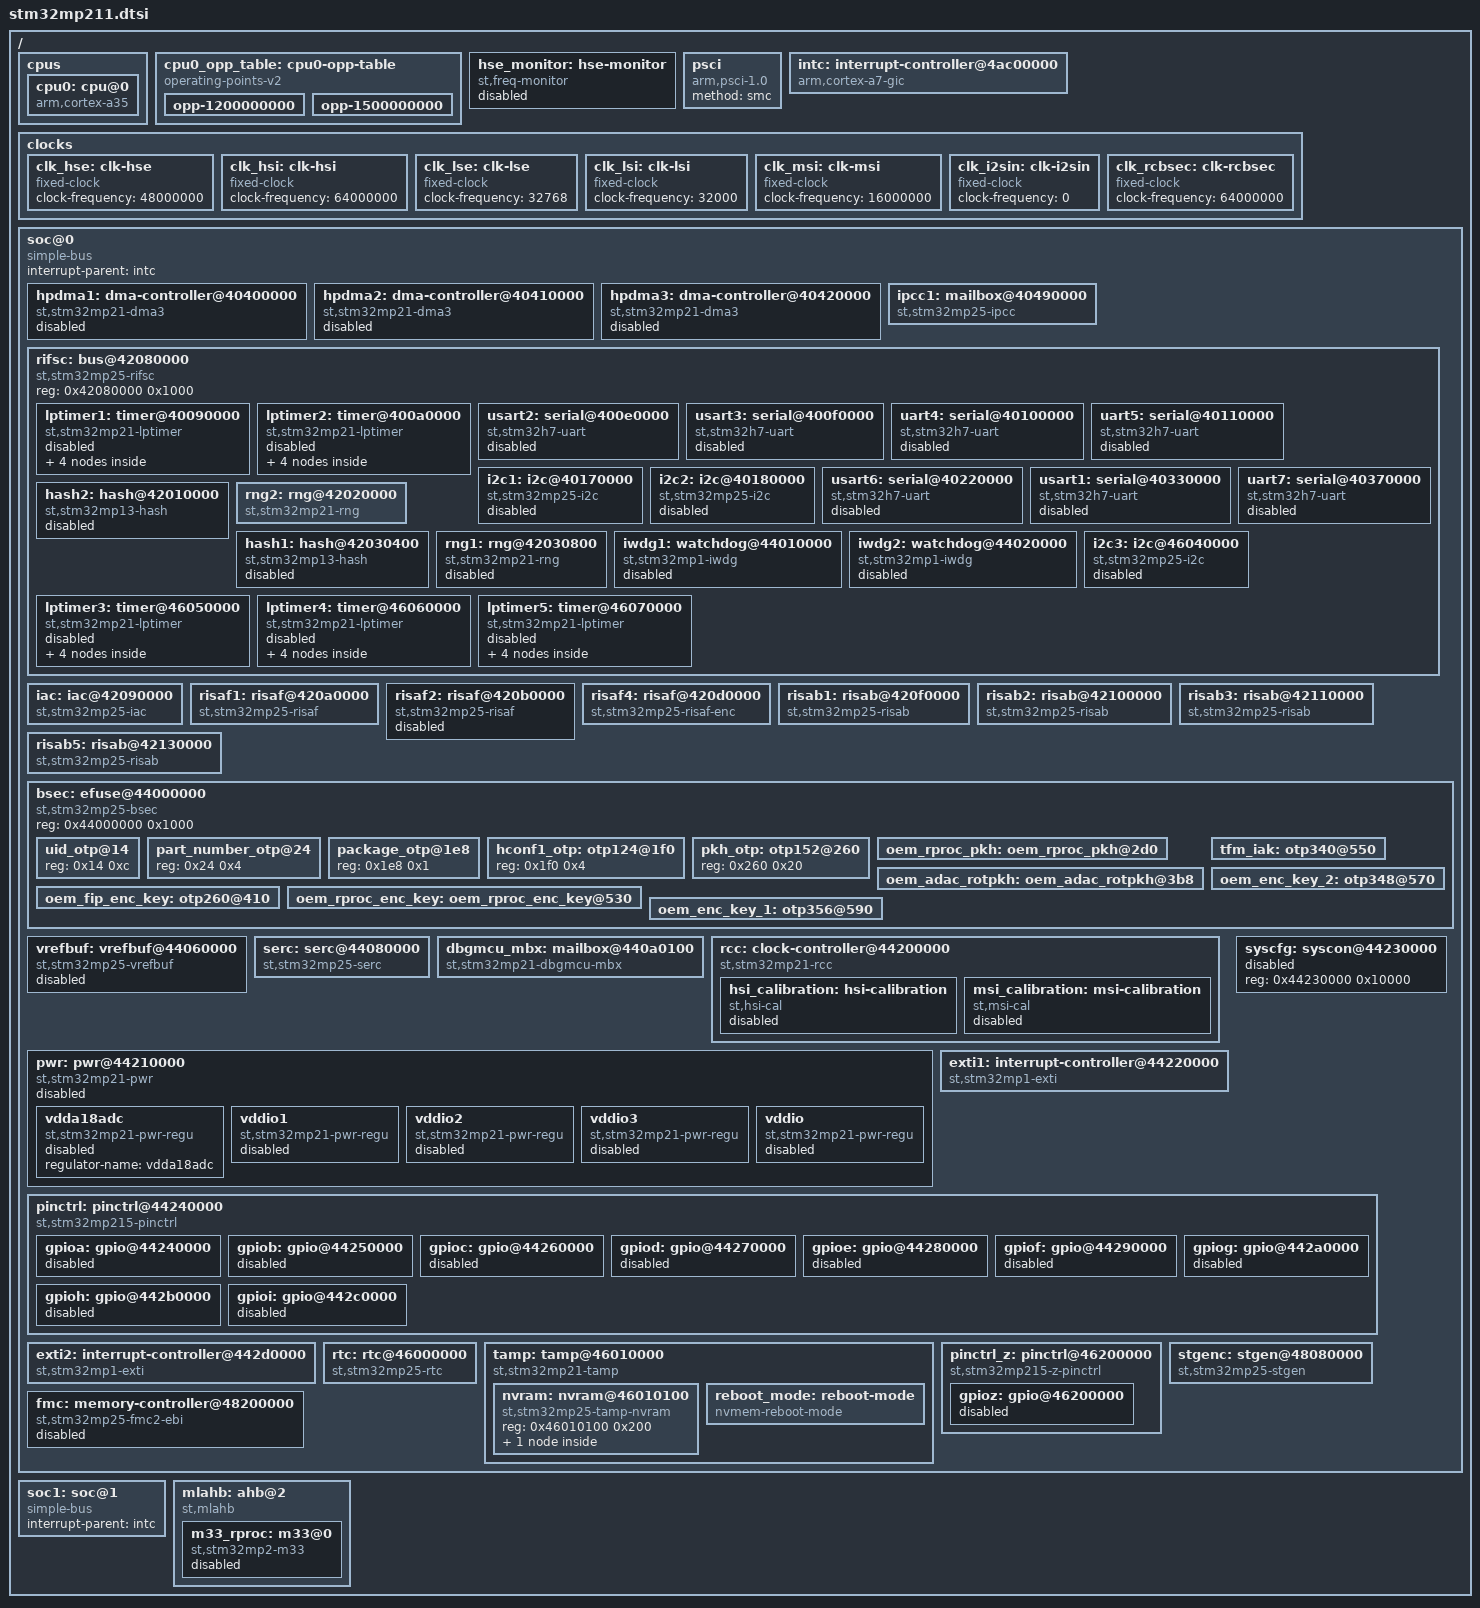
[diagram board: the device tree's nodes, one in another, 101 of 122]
// SPDX-License-Identifier: (GPL-2.0-only OR BSD-3-Clause)
/*
 * Copyright (C) 2025, STMicroelectronics - All Rights Reserved
 * Author: Alexandre Torgue <alexandre.torgue@foss.st.com> for STMicroelectronics.
 */
#include <dt-bindings/clock/st,stm32mp21-rcc.h>
#include <dt-bindings/gpio/gpio.h>
#include <dt-bindings/interrupt-controller/arm-gic.h>
#include <dt-bindings/firewall/stm32mp21-rifsc.h>
#include <dt-bindings/firewall/stm32mp25-rif.h>
#include <dt-bindings/firewall/stm32mp25-risab.h>
#include <dt-bindings/firewall/stm32mp25-risaf.h>
#include <dt-bindings/reset/st,stm32mp21-rcc.h>

/ {
	#address-cells = <2>;
	#size-cells = <2>;

	cpus {
		#address-cells = <1>;
		#size-cells = <0>;

		cpu0: cpu@0 {
			compatible = "arm,cortex-a35";
			device_type = "cpu";
			reg = <0>;
			enable-method = "psci";
			operating-points-v2 = <&cpu0_opp_table>;
			clocks = <&rcc CK_CPU1>;
		};
	};

	cpu0_opp_table: cpu0-opp-table {
		compatible = "operating-points-v2";

		opp-1200000000 {
			opp-hz = /bits/ 64 <1200000000>;
			opp-microvolt = <800000>;
			opp-supported-hw = <0x3>;
			st,opp-default;
		};

		opp-1500000000 {
			opp-hz = /bits/ 64 <1500000000>;
			opp-microvolt = <910000>;
			opp-supported-hw = <0x2>;
		};
	};

	hse_monitor: hse-monitor {
		compatible = "st,freq-monitor";
		counter = <&lptimer1 1 5 1 1>;
		clocks = <&rcc HSE_CK>, <&rcc HSI_CK>;
		clock-names = "hse", "hsi";
		status = "disabled";
	};

	psci {
		compatible = "arm,psci-1.0";
		method = "smc";
	};

	intc: interrupt-controller@4ac00000 {
		compatible = "arm,cortex-a7-gic";
		#interrupt-cells = <3>;
		interrupt-controller;
		reg = <0x0 0x4ac10000 0x0 0x1000>,
		      <0x0 0x4ac20000 0x0 0x2000>,
		      <0x0 0x4ac40000 0x0 0x2000>,
		      <0x0 0x4ac60000 0x0 0x2000>;
		#address-cells = <1>;
	};

	clocks {
		clk_hse: clk-hse {
			#clock-cells = <0>;
			compatible = "fixed-clock";
			clock-frequency = <48000000>;
		};

		clk_hsi: clk-hsi {
			#clock-cells = <0>;
			compatible = "fixed-clock";
			clock-frequency = <64000000>;
		};

		clk_lse: clk-lse {
			#clock-cells = <0>;
			compatible = "fixed-clock";
			clock-frequency = <32768>;
		};

		clk_lsi: clk-lsi {
			#clock-cells = <0>;
			compatible = "fixed-clock";
			clock-frequency = <32000>;
		};

		clk_msi: clk-msi {
			#clock-cells = <0>;
			compatible = "fixed-clock";
			clock-frequency = <16000000>;
		};

		clk_i2sin: clk-i2sin {
			#clock-cells = <0>;
			compatible = "fixed-clock";
			clock-frequency = <0>;
		};

		clk_rcbsec: clk-rcbsec {
			#clock-cells = <0>;
			compatible = "fixed-clock";
			clock-frequency = <64000000>;
		};
	};

	soc@0 {
		compatible = "simple-bus";
		#address-cells = <1>;
		#size-cells = <1>;
		interrupt-parent = <&intc>;
		ranges = <0x0 0x0 0x0 0x80000000>;

		hpdma1: dma-controller@40400000 {
			compatible = "st,stm32mp21-dma3";
			reg = <0x40400000 0x1000>;
			clocks = <&rcc CK_BUS_HPDMA1>;
			#dma-cells = <3>;
			st,syscfg-arcr = <&syscfg 0x2050 0x1>;
			status = "disabled";
		};

		hpdma2: dma-controller@40410000 {
			compatible = "st,stm32mp21-dma3";
			reg = <0x40410000 0x1000>;
			clocks = <&rcc CK_BUS_HPDMA2>;
			#dma-cells = <3>;
			st,syscfg-arcr = <&syscfg 0x2050 0x2>;
			status = "disabled";
		};

		hpdma3: dma-controller@40420000 {
			compatible = "st,stm32mp21-dma3";
			reg = <0x40420000 0x1000>;
			clocks = <&rcc CK_BUS_HPDMA3>;
			#dma-cells = <3>;
			st,syscfg-arcr = <&syscfg 0x2050 0x4>;
			status = "disabled";
		};

		ipcc1: mailbox@40490000 {
			compatible = "st,stm32mp25-ipcc";
			reg = <0x40490000 0x400>;
			#mbox-cells = <1>;
			interrupts = <GIC_SPI 154 IRQ_TYPE_LEVEL_HIGH>;
			interrupt-names = "rx";
			clocks = <&rcc CK_BUS_IPCC1>;
			st,proc-id = <0>;
		};

		rifsc: bus@42080000 {
			compatible = "st,stm32mp25-rifsc", "simple-bus";
			reg = <0x42080000 0x1000>;
			#address-cells = <1>;
			#size-cells = <1>;
			#access-controller-cells = <1>;

			lptimer1: timer@40090000 {
				compatible = "st,stm32mp21-lptimer";
				reg = <0x40090000 0x400>;
				interrupts = <GIC_SPI 149 IRQ_TYPE_LEVEL_HIGH>;
				clocks = <&rcc CK_KER_LPTIM1>;
				clock-names = "mux";
				#address-cells = <1>;
				#size-cells = <0>;
				access-controllers = <&rifsc STM32MP21_RIFSC_LPTIM1_ID>;
				status = "disabled";

				counter {
					compatible = "st,stm32mp21-lptimer-counter";
					status = "disabled";
				};

				pwm {
					compatible = "st,stm32mp21-pwm-lp";
					#pwm-cells = <3>;
					status = "disabled";
				};

				timer {
					compatible = "st,stm32mp21-lptimer-timer";
					status = "disabled";
				};

				trigger@0 {
					compatible = "st,stm32mp21-lptimer-trigger";
					reg = <0>;
					status = "disabled";
				};
			};

			lptimer2: timer@400a0000 {
				compatible = "st,stm32mp21-lptimer";
				reg = <0x400a0000 0x400>;
				interrupts = <GIC_SPI 180 IRQ_TYPE_LEVEL_HIGH>;
				clocks = <&rcc CK_KER_LPTIM2>;
				clock-names = "mux";
				#address-cells = <1>;
				#size-cells = <0>;
				access-controllers = <&rifsc STM32MP21_RIFSC_LPTIM2_ID>;
				status = "disabled";

				counter {
					compatible = "st,stm32mp21-lptimer-counter";
					status = "disabled";
				};

				pwm {
					compatible = "st,stm32mp21-pwm-lp";
					#pwm-cells = <3>;
					status = "disabled";
				};

				timer {
					compatible = "st,stm32mp21-lptimer-timer";
					status = "disabled";
				};

				trigger@1 {
					compatible = "st,stm32mp21-lptimer-trigger";
					reg = <1>;
					status = "disabled";
				};
			};

			usart2: serial@400e0000 {
				compatible = "st,stm32h7-uart";
				reg = <0x400e0000 0x400>;
				interrupts = <GIC_SPI 102 IRQ_TYPE_LEVEL_HIGH>;
				clocks = <&rcc CK_KER_USART2>;
				access-controllers = <&rifsc STM32MP21_RIFSC_USART2_ID>;
				status = "disabled";
			};

			usart3: serial@400f0000 {
				compatible = "st,stm32h7-uart";
				reg = <0x400f0000 0x400>;
				interrupts = <GIC_SPI 103 IRQ_TYPE_LEVEL_HIGH>;
				clocks = <&rcc CK_KER_USART3>;
				access-controllers = <&rifsc STM32MP21_RIFSC_USART3_ID>;
				status = "disabled";
			};

			uart4: serial@40100000 {
				compatible = "st,stm32h7-uart";
				reg = <0x40100000 0x400>;
				interrupts = <GIC_SPI 113 IRQ_TYPE_LEVEL_HIGH>;
				clocks = <&rcc CK_KER_UART4>;
				access-controllers = <&rifsc STM32MP21_RIFSC_UART4_ID>;
				status = "disabled";
			};

			uart5: serial@40110000 {
				compatible = "st,stm32h7-uart";
				reg = <0x40110000 0x400>;
				interrupts = <GIC_SPI 114 IRQ_TYPE_LEVEL_HIGH>;
				clocks = <&rcc CK_KER_UART5>;
				access-controllers = <&rifsc STM32MP21_RIFSC_UART5_ID>;
				status = "disabled";
			};

			i2c1: i2c@40170000 {
				compatible = "st,stm32mp25-i2c";
				reg = <0x40170000 0x400>;
				clocks = <&rcc CK_KER_I2C1>;
				resets = <&rcc I2C1_R>;
				#address-cells = <1>;
				#size-cells = <0>;
				access-controllers = <&rifsc STM32MP21_RIFSC_I2C1_ID>;
				status = "disabled";
			};

			i2c2: i2c@40180000 {
				compatible = "st,stm32mp25-i2c";
				reg = <0x40180000 0x400>;
				clocks = <&rcc CK_KER_I2C1>;
				resets = <&rcc I2C1_R>;
				#address-cells = <1>;
				#size-cells = <0>;
				access-controllers = <&rifsc STM32MP21_RIFSC_I2C2_ID>;
				status = "disabled";
			};

			usart6: serial@40220000 {
				compatible = "st,stm32h7-uart";
				reg = <0x40220000 0x400>;
				interrupts = <GIC_SPI 123 IRQ_TYPE_LEVEL_HIGH>;
				clocks = <&rcc CK_KER_USART6>;
				access-controllers = <&rifsc STM32MP21_RIFSC_USART6_ID>;
				status = "disabled";
			};

			usart1: serial@40330000 {
				compatible = "st,stm32h7-uart";
				reg = <0x40330000 0x400>;
				interrupts = <GIC_SPI 101 IRQ_TYPE_LEVEL_HIGH>;
				clocks = <&rcc CK_KER_USART1>;
				access-controllers = <&rifsc STM32MP21_RIFSC_USART1_ID>;
				status = "disabled";
			};

			uart7: serial@40370000 {
				compatible = "st,stm32h7-uart";
				reg = <0x40370000 0x400>;
				interrupts = <GIC_SPI 135 IRQ_TYPE_LEVEL_HIGH>;
				clocks = <&rcc CK_KER_UART7>;
				access-controllers = <&rifsc STM32MP21_RIFSC_UART7_ID>;
				status = "disabled";
			};

			hash2: hash@42010000  {
				compatible = "st,stm32mp13-hash";
				reg = <0x42010000  0x400>;
				interrupts = <GIC_SPI 178 IRQ_TYPE_LEVEL_HIGH>;
				clocks = <&rcc CK_BUS_HASH2>;
				resets = <&rcc HASH2_R>;
				access-controllers = <&rifsc STM32MP21_RIFSC_HASH2_ID>;
				status = "disabled";
			};

			rng2: rng@42020000 {
				compatible = "st,stm32mp21-rng";
				reg = <0x42020000 0x400>;
				clocks = <&clk_rcbsec>, <&rcc CK_BUS_RNG2>;
				clock-names = "core", "bus";
				access-controllers = <&rifsc STM32MP21_RIFSC_RNG2_ID>;
				resets = <&rcc RNG2_R>;
			};

			hash1: hash@42030400 {
				compatible = "st,stm32mp13-hash";
				reg = <0x42030400  0x400>;
				interrupts = <GIC_SPI 132 IRQ_TYPE_LEVEL_HIGH>;
				clocks = <&rcc CK_BUS_HASH1>;
				resets = <&rcc HASH1_R>;
				access-controllers = <&rifsc STM32MP21_RIFSC_HASH1_ID>;
				status = "disabled";
			};

			rng1: rng@42030800 {
				compatible = "st,stm32mp21-rng";
				reg = <0x42030800 0x400>;
				clocks = <&clk_rcbsec>, <&rcc CK_BUS_RNG1>;
				clock-names = "core", "bus";
				resets = <&rcc RNG1_R>;
				access-controllers = <&rifsc STM32MP21_RIFSC_RNG1_ID>;
				status = "disabled";
			};

			iwdg1: watchdog@44010000 {
				compatible = "st,stm32mp1-iwdg";
				reg = <0x44010000 0x400>;
				interrupts = <GIC_SPI 2 IRQ_TYPE_LEVEL_HIGH>;
				clocks = <&rcc CK_BUS_IWDG1>, <&rcc LSI_CK>;
				clock-names = "pclk", "lsi";
				access-controllers = <&rifsc STM32MP21_RIFSC_IWDG1_ID>;
				status = "disabled";
			};

			iwdg2: watchdog@44020000 {
				compatible = "st,stm32mp1-iwdg";
				reg = <0x44020000 0x400>;
				interrupts = <GIC_SPI 3 IRQ_TYPE_LEVEL_HIGH>;
				clocks = <&rcc CK_BUS_IWDG2>, <&rcc LSI_CK>;
				clock-names = "pclk", "lsi";
				resets = <&rcc IWDG2_SYS_R>;
				access-controllers = <&rifsc STM32MP21_RIFSC_IWDG2_ID>;
				status = "disabled";
			};

			i2c3: i2c@46040000 {
				compatible = "st,stm32mp25-i2c";
				reg = <0x46040000 0x400>;
				clocks = <&rcc CK_KER_I2C3>;
				resets = <&rcc I2C3_R>;
				#address-cells = <1>;
				#size-cells = <0>;
				access-controllers = <&rifsc STM32MP21_RIFSC_I2C3_ID>;
				status = "disabled";
			};

			lptimer3: timer@46050000 {
				compatible = "st,stm32mp21-lptimer";
				reg = <0x46050000 0x400>;
				interrupts = <GIC_SPI 181 IRQ_TYPE_LEVEL_HIGH>;
				clocks = <&rcc CK_KER_LPTIM3>;
				clock-names = "mux";
				#address-cells = <1>;
				#size-cells = <0>;
				access-controllers = <&rifsc STM32MP21_RIFSC_LPTIM3_ID>;
				status = "disabled";

				counter {
					compatible = "st,stm32mp21-lptimer-counter";
					status = "disabled";
				};

				pwm {
					compatible = "st,stm32mp21-pwm-lp";
					#pwm-cells = <3>;
					status = "disabled";
				};

				timer {
					compatible = "st,stm32mp21-lptimer-timer";
					status = "disabled";
				};

				trigger@2 {
					compatible = "st,stm32mp21-lptimer-trigger";
					reg = <2>;
					status = "disabled";
				};
			};

			lptimer4: timer@46060000 {
				compatible = "st,stm32mp21-lptimer";
				reg = <0x46060000 0x400>;
				interrupts = <GIC_SPI 182 IRQ_TYPE_LEVEL_HIGH>;
				clocks = <&rcc CK_KER_LPTIM4>;
				clock-names = "mux";
				#address-cells = <1>;
				#size-cells = <0>;
				access-controllers = <&rifsc STM32MP21_RIFSC_LPTIM4_ID>;
				status = "disabled";

				counter {
					compatible = "st,stm32mp21-lptimer-counter";
					status = "disabled";
				};

				pwm {
					compatible = "st,stm32mp21-pwm-lp";
					#pwm-cells = <3>;
					status = "disabled";
				};

				timer {
					compatible = "st,stm32mp21-lptimer-timer";
					status = "disabled";
				};

				trigger@3 {
					compatible = "st,stm32mp21-lptimer-trigger";
					reg = <3>;
					status = "disabled";
				};
			};

			lptimer5: timer@46070000 {
				compatible = "st,stm32mp21-lptimer";
				reg = <0x46070000 0x400>;
				interrupts = <GIC_SPI 183 IRQ_TYPE_LEVEL_HIGH>;
				clocks = <&rcc CK_KER_LPTIM5>;
				clock-names = "mux";
				#address-cells = <1>;
				#size-cells = <0>;
				access-controllers = <&rifsc STM32MP21_RIFSC_LPTIM5_ID>;
				status = "disabled";

				counter {
					compatible = "st,stm32mp21-lptimer-counter";
					status = "disabled";
				};

				pwm {
					compatible = "st,stm32mp21-pwm-lp";
					#pwm-cells = <3>;
					status = "disabled";
				};

				timer {
					compatible = "st,stm32mp21-lptimer-timer";
					status = "disabled";
				};

				trigger@4 {
					compatible = "st,stm32mp21-lptimer-trigger";
					reg = <4>;
					status = "disabled";
				};
			};
		};

		iac: iac@42090000 {
			compatible = "st,stm32mp25-iac";
			reg = <0x42090000 0x400>;
			interrupts = <GIC_SPI 201 IRQ_TYPE_LEVEL_HIGH>;
		};

		risaf1: risaf@420a0000 {
			compatible = "st,stm32mp25-risaf";
			reg = <0x420a0000 0x1000>;
			clocks = <&rcc CK_BUS_BKPSRAM>;
			st,mem-map = <0x0 0x42000000 0x0 0x2000>;
			#access-controller-cells = <1>;
		};

		risaf2: risaf@420b0000 {
			compatible = "st,stm32mp25-risaf";
			reg = <0x420b0000 0x1000>;
			clocks = <&rcc CK_KER_OSPI1>;
			st,mem-map = <0x0 0x60000000 0x0 0x10000000>;
			status = "disabled";
			#access-controller-cells = <1>;
		};

		risaf4: risaf@420d0000 {
			compatible = "st,stm32mp25-risaf-enc";
			reg = <0x420d0000 0x1000>;
			clocks = <&rcc CK_BUS_RISAF4>;
			st,mem-map = <0x0 0x80000000 0x1 0x00000000>;
			#access-controller-cells = <1>;
		};

		risab1: risab@420f0000 {
			compatible = "st,stm32mp25-risab";
			reg = <0x420f0000 0x1000>;
			clocks = <&rcc CK_ICN_LS_MCU>;
			st,mem-map = <0xa000000 0x20000>;
			#access-controller-cells = <1>;
		};

		risab2: risab@42100000 {
			compatible = "st,stm32mp25-risab";
			reg = <0x42100000 0x1000>;
			clocks = <&rcc CK_ICN_LS_MCU>;
			st,mem-map = <0xa020000 0x20000>;
			#access-controller-cells = <1>;
		};

		risab3: risab@42110000 {
			compatible = "st,stm32mp25-risab";
			reg = <0x42110000 0x1000>;
			clocks = <&rcc CK_ICN_LS_MCU>;
			st,mem-map = <0x0a060000 0x10000>;
			#access-controller-cells = <1>;
		};

		risab5: risab@42130000 {
			compatible = "st,stm32mp25-risab";
			reg = <0x42130000 0x1000>;
			clocks = <&rcc CK_ICN_LS_MCU>;
			st,mem-map = <0x0a040000 0x20000>;
			#access-controller-cells = <1>;
		};

		bsec: efuse@44000000 {
			compatible = "st,stm32mp25-bsec";
			reg = <0x44000000 0x1000>;
			#address-cells = <1>;
			#size-cells = <1>;

			uid_otp@14 {
				/* 0x14 -> otp5 */
				reg = <0x14 0xc>;
			};

			part_number_otp@24 {
				reg = <0x24 0x4>;
			};

			package_otp@1e8 {
				reg = <0x1e8 0x1>;
			};

			hconf1_otp: otp124@1f0 {
				reg = <0x1f0 0x4>;
			};

			pkh_otp: otp152@260 {
				reg = <0x260 0x20>;
			};

			oem_rproc_pkh: oem_rproc_pkh@2d0 {
				/* 0x2D0 -> otp180 */
				reg = <0x2D0 0x20>;
				st,non-secure-otp-provisioning;
			};

			oem_adac_rotpkh: oem_adac_rotpkh@3b8 {
				/* 0x3b8 -> otp238 */
				reg = <0x3b8 0x20>;
				st,non-secure-otp-provisioning;
			};

			oem_fip_enc_key: otp260@410 {
				reg = <0x410 0x20>;
				st,non-secure-otp-provisioning;
			};

			oem_rproc_enc_key: oem_rproc_enc_key@530 {
				/* 0x530 -> otp332 */
				reg = <0x530 0x20>;
				st,non-secure-otp-provisioning;
			};

			tfm_iak: otp340@550 {
				reg = <0x550 0x20>;
				st,non-secure-otp-provisioning;
			};

			oem_enc_key_2: otp348@570 {
				reg = <0x570 0x20>;
				st,non-secure-otp-provisioning;
			};

			oem_enc_key_1: otp356@590 {
				reg = <0x590 0x20>;
				st,non-secure-otp-provisioning;
			};
		};

		vrefbuf: vrefbuf@44060000 {
			compatible = "st,stm32mp25-vrefbuf";
			reg = <0x44060000 0x8>;
			regulator-name = "vrefbuf";
			regulator-min-microvolt = <1210000>;
			regulator-max-microvolt = <1500000>;
			clocks = <&rcc CK_BUS_VREF>;
			vdda-supply = <&vdda18adc>;
			status = "disabled";
		};

		serc: serc@44080000 {
			compatible = "st,stm32mp25-serc";
			reg = <0x44080000 0x1000>;
			interrupts = <GIC_SPI 195 IRQ_TYPE_LEVEL_HIGH>;
			clocks = <&rcc CK_BUS_SERC>;
		};

		dbgmcu_mbx: mailbox@440a0100 {
			compatible = "st,stm32mp21-dbgmcu-mbx";
			reg = <0x440a0100 0xc>;
			interrupts = <GIC_SPI 208 IRQ_TYPE_LEVEL_HIGH>,
				     <GIC_SPI 209 IRQ_TYPE_EDGE_RISING>;
			interrupt-names = "dbg_auth_wr", "dbg_auth_rd";
			clocks = <&rcc CK_DBGMCU>;
		};

		rcc: clock-controller@44200000 {
			compatible = "st,stm32mp21-rcc", "syscon";
			reg = <0x44200000 0x10000>;
			interrupts = <GIC_SPI 186 IRQ_TYPE_LEVEL_HIGH>;

			#clock-cells = <1>;
			#reset-cells = <1>;
			clocks = <&clk_hse>, <&clk_hsi>, <&clk_lse>,
				 <&clk_lsi>, <&clk_msi>, <&clk_i2sin>;
			clock-names = "clk-hse", "clk-hsi", "clk-lse",
				      "clk-lsi", "clk-msi", "clk-i2sin";

			hsi_calibration: hsi-calibration {
				compatible = "st,hsi-cal";
				st,cal_hsi_dev = <31>;
				st,cal_hsi_ref = <1953>;
				status = "disabled";
			};

			msi_calibration: msi-calibration {
				compatible = "st,msi-cal";
				status = "disabled";
			};
		};

		pwr: pwr@44210000 {
			compatible = "st,stm32mp21-pwr";
			reg = <0x44210000 0x400>;
			interrupts = <GIC_SPI 190 IRQ_TYPE_LEVEL_HIGH>;
			interrupt-controller;
			#interrupt-cells = <2>;
			wakeup-gpios = <0>, <0>, <0>, <0>, <0>, <0>;
			status = "disabled";

			vdda18adc: vdda18adc {
				compatible = "st,stm32mp21-pwr-regu";
				regulator-name = "vdda18adc";
				status = "disabled";
			};

			vddio1: vddio1 {
				compatible = "st,stm32mp21-pwr-regu";
				regulator-name = "vddio1";
				st,iocomp = <8 7>;
				status = "disabled";
			};

			vddio2: vddio2 {
				compatible = "st,stm32mp21-pwr-regu";
				regulator-name = "vddio2";
				st,iocomp = <8 7>;
				status = "disabled";
			};

			vddio3: vddio3 {
				compatible = "st,stm32mp21-pwr-regu";
				regulator-name = "vddio3";
				st,iocomp = <8 7>;
				status = "disabled";
			};

			vddio: vddio {
				compatible = "st,stm32mp21-pwr-regu";
				regulator-name = "vddio";
				st,iocomp = <8 7>;
				regulator-always-on;
				status = "disabled";
			};
		};

		exti1: interrupt-controller@44220000 {
			compatible = "st,stm32mp1-exti";
			wakeup-parent = <&pwr>;
			interrupt-controller;
			#interrupt-cells = <2>;
			reg = <0x44220000 0x400>;
			interrupts-extended =
				<&intc GIC_SPI 268 IRQ_TYPE_LEVEL_HIGH>,	/* EXTI_0 */
				<&intc GIC_SPI 269 IRQ_TYPE_LEVEL_HIGH>,
				<&intc GIC_SPI 270 IRQ_TYPE_LEVEL_HIGH>,
				<&intc GIC_SPI 271 IRQ_TYPE_LEVEL_HIGH>,
				<&intc GIC_SPI 272 IRQ_TYPE_LEVEL_HIGH>,
				<&intc GIC_SPI 273 IRQ_TYPE_LEVEL_HIGH>,
				<&intc GIC_SPI 274 IRQ_TYPE_LEVEL_HIGH>,
				<&intc GIC_SPI 275 IRQ_TYPE_LEVEL_HIGH>,
				<&intc GIC_SPI 276 IRQ_TYPE_LEVEL_HIGH>,
				<&intc GIC_SPI 277 IRQ_TYPE_LEVEL_HIGH>,
				<&intc GIC_SPI 278 IRQ_TYPE_LEVEL_HIGH>,	/* EXTI_10 */
				<&intc GIC_SPI 279 IRQ_TYPE_LEVEL_HIGH>,
				<&intc GIC_SPI 280 IRQ_TYPE_LEVEL_HIGH>,
				<&intc GIC_SPI 281 IRQ_TYPE_LEVEL_HIGH>,
				<&intc GIC_SPI 282 IRQ_TYPE_LEVEL_HIGH>,
				<&intc GIC_SPI 283 IRQ_TYPE_LEVEL_HIGH>,
				<&intc GIC_SPI 0   IRQ_TYPE_LEVEL_HIGH>,
				<&intc GIC_SPI 1   IRQ_TYPE_LEVEL_HIGH>,
				<&intc GIC_SPI 211 IRQ_TYPE_LEVEL_HIGH>,
				<&intc GIC_SPI 210 IRQ_TYPE_LEVEL_HIGH>,
				<0>,						/* EXTI_20 */
				<&intc GIC_SPI 95  IRQ_TYPE_LEVEL_HIGH>,
				<&intc GIC_SPI 97  IRQ_TYPE_LEVEL_HIGH>,
				<&intc GIC_SPI 124 IRQ_TYPE_LEVEL_HIGH>,
				<0>,
				<0>,
				<&intc GIC_SPI 101 IRQ_TYPE_LEVEL_HIGH>,
				<&intc GIC_SPI 102 IRQ_TYPE_LEVEL_HIGH>,
				<&intc GIC_SPI 103 IRQ_TYPE_LEVEL_HIGH>,
				<&intc GIC_SPI 123 IRQ_TYPE_LEVEL_HIGH>,
				<&intc GIC_SPI 113 IRQ_TYPE_LEVEL_HIGH>,	/* EXTI_30 */
				<&intc GIC_SPI 114 IRQ_TYPE_LEVEL_HIGH>,
				<&intc GIC_SPI 135 IRQ_TYPE_LEVEL_HIGH>,
				<0>,
				<0>,
				<0>,
				<&intc GIC_SPI 99  IRQ_TYPE_LEVEL_HIGH>,
				<&intc GIC_SPI 100 IRQ_TYPE_LEVEL_HIGH>,
				<&intc GIC_SPI 112 IRQ_TYPE_LEVEL_HIGH>,
				<&intc GIC_SPI 137 IRQ_TYPE_LEVEL_HIGH>,
				<&intc GIC_SPI 138 IRQ_TYPE_LEVEL_HIGH>,	/* EXTI_40 */
				<&intc GIC_SPI 139 IRQ_TYPE_LEVEL_HIGH>,
				<0>,
				<&intc GIC_SPI 150 IRQ_TYPE_LEVEL_HIGH>,
				<&intc GIC_SPI 158 IRQ_TYPE_LEVEL_HIGH>,
				<0>,
				<0>,
				<&intc GIC_SPI 149 IRQ_TYPE_LEVEL_HIGH>,
				<&intc GIC_SPI 180 IRQ_TYPE_LEVEL_HIGH>,
				<0>,
				<0>,						/* EXTI_50 */
				<0>,
				<&pwr 0 IRQ_TYPE_EDGE_FALLING>,
				<&pwr 1 IRQ_TYPE_EDGE_FALLING>,
				<&pwr 2 IRQ_TYPE_EDGE_FALLING>,
				<&pwr 3 IRQ_TYPE_EDGE_FALLING>,
				<&pwr 4 IRQ_TYPE_EDGE_FALLING>,
				<&pwr 5 IRQ_TYPE_EDGE_FALLING>,
				<0>,
				<&intc GIC_SPI 152 IRQ_TYPE_LEVEL_HIGH>,
				<0>,						/* EXTI_60 */
				<&intc GIC_SPI 154 IRQ_TYPE_LEVEL_HIGH>,
				<0>,
				<0>,
				<&intc GIC_SPI 185 IRQ_TYPE_LEVEL_HIGH>,
				<0>,
				<0>,
				<&intc GIC_SPI 9   IRQ_TYPE_LEVEL_HIGH>,
				<&intc GIC_SPI 118 IRQ_TYPE_LEVEL_HIGH>,
				<0>,
				<&intc GIC_SPI 121 IRQ_TYPE_LEVEL_HIGH>,	/* EXTI_70 */
				<0>,
				<&intc GIC_SPI 188 IRQ_TYPE_LEVEL_HIGH>,
				<&intc GIC_SPI 172 IRQ_TYPE_LEVEL_HIGH>,
				<&intc GIC_SPI 96  IRQ_TYPE_LEVEL_HIGH>,
				<&intc GIC_SPI 98  IRQ_TYPE_LEVEL_HIGH>,
				<&intc GIC_SPI 125 IRQ_TYPE_LEVEL_HIGH>,
				<&intc GIC_SPI 205 IRQ_TYPE_LEVEL_HIGH>,
				<&intc GIC_SPI 206 IRQ_TYPE_LEVEL_HIGH>,
				<&intc GIC_SPI 207 IRQ_TYPE_LEVEL_HIGH>;
		};

		syscfg: syscon@44230000 {
			reg = <0x44230000 0x10000>;
			status = "disabled";
		};

		pinctrl: pinctrl@44240000 {
			#address-cells = <1>;
			#size-cells = <1>;
			compatible = "st,stm32mp215-pinctrl";
			ranges = <0 0x44240000 0x80400>;

			gpioa: gpio@44240000 {
				gpio-controller;
				#gpio-cells = <2>;
				interrupt-controller;
				#interrupt-cells = <2>;
				#access-controller-cells = <1>;
				reg = <0x0 0x400>;
				clocks = <&rcc CK_BUS_GPIOA>;
				st,bank-name = "GPIOA";
				status = "disabled";
			};

			gpiob: gpio@44250000 {
				gpio-controller;
				#gpio-cells = <2>;
				interrupt-controller;
				#interrupt-cells = <2>;
				#access-controller-cells = <1>;
				reg = <0x10000 0x400>;
				clocks = <&rcc CK_BUS_GPIOB>;
				st,bank-name = "GPIOB";
				status = "disabled";
			};

			gpioc: gpio@44260000 {
				gpio-controller;
				#gpio-cells = <2>;
				interrupt-controller;
				#interrupt-cells = <2>;
				#access-controller-cells = <1>;
				reg = <0x20000 0x400>;
				clocks = <&rcc CK_BUS_GPIOC>;
				st,bank-name = "GPIOC";
				status = "disabled";
			};

			gpiod: gpio@44270000 {
				gpio-controller;
				#gpio-cells = <2>;
				interrupt-controller;
				#interrupt-cells = <2>;
				#access-controller-cells = <1>;
				reg = <0x30000 0x400>;
				clocks = <&rcc CK_BUS_GPIOD>;
				st,bank-name = "GPIOD";
				status = "disabled";
			};

			gpioe: gpio@44280000 {
				gpio-controller;
				#gpio-cells = <2>;
				interrupt-controller;
				#interrupt-cells = <2>;
				#access-controller-cells = <1>;
				reg = <0x40000 0x400>;
				clocks = <&rcc CK_BUS_GPIOE>;
				st,bank-name = "GPIOE";
				status = "disabled";
			};

			gpiof: gpio@44290000 {
				gpio-controller;
				#gpio-cells = <2>;
				interrupt-controller;
				#interrupt-cells = <2>;
				#access-controller-cells = <1>;
				reg = <0x50000 0x400>;
				clocks = <&rcc CK_BUS_GPIOF>;
				st,bank-name = "GPIOF";
				status = "disabled";
			};

			gpiog: gpio@442a0000 {
				gpio-controller;
				#gpio-cells = <2>;
				interrupt-controller;
				#interrupt-cells = <2>;
				#access-controller-cells = <1>;
				reg = <0x60000 0x400>;
				clocks = <&rcc CK_BUS_GPIOG>;
				st,bank-name = "GPIOG";
				status = "disabled";
			};

			gpioh: gpio@442b0000 {
				gpio-controller;
				#gpio-cells = <2>;
				interrupt-controller;
				#interrupt-cells = <2>;
				#access-controller-cells = <1>;
				reg = <0x70000 0x400>;
				clocks = <&rcc CK_BUS_GPIOH>;
				st,bank-name = "GPIOH";
				status = "disabled";
			};

			gpioi: gpio@442c0000 {
				gpio-controller;
				#gpio-cells = <2>;
				interrupt-controller;
				#interrupt-cells = <2>;
				#access-controller-cells = <1>;
				reg = <0x80000 0x400>;
				clocks = <&rcc CK_BUS_GPIOI>;
				st,bank-name = "GPIOI";
				status = "disabled";
			};
		};

		exti2: interrupt-controller@442d0000 {
			compatible = "st,stm32mp1-exti";
			interrupt-controller;
			#interrupt-cells = <2>;
			reg = <0x442d0000 0x400>;
			interrupts-extended =
				<&intc GIC_SPI 15  IRQ_TYPE_LEVEL_HIGH>,	/* EXTI_0 */
				<&intc GIC_SPI 16  IRQ_TYPE_LEVEL_HIGH>,
				<&intc GIC_SPI 17  IRQ_TYPE_LEVEL_HIGH>,
				<&intc GIC_SPI 18  IRQ_TYPE_LEVEL_HIGH>,
				<&intc GIC_SPI 19  IRQ_TYPE_LEVEL_HIGH>,
				<&intc GIC_SPI 20  IRQ_TYPE_LEVEL_HIGH>,
				<&intc GIC_SPI 21  IRQ_TYPE_LEVEL_HIGH>,
				<&intc GIC_SPI 22  IRQ_TYPE_LEVEL_HIGH>,
				<&intc GIC_SPI 23  IRQ_TYPE_LEVEL_HIGH>,
				<&intc GIC_SPI 24  IRQ_TYPE_LEVEL_HIGH>,
				<&intc GIC_SPI 25  IRQ_TYPE_LEVEL_HIGH>,	/* EXTI_10 */
				<&intc GIC_SPI 26  IRQ_TYPE_LEVEL_HIGH>,
				<&intc GIC_SPI 27  IRQ_TYPE_LEVEL_HIGH>,
				<&intc GIC_SPI 28  IRQ_TYPE_LEVEL_HIGH>,
				<&intc GIC_SPI 29  IRQ_TYPE_LEVEL_HIGH>,
				<&intc GIC_SPI 30  IRQ_TYPE_LEVEL_HIGH>,
				<&intc GIC_SPI 10  IRQ_TYPE_LEVEL_HIGH>,
				<&intc GIC_SPI 11  IRQ_TYPE_LEVEL_HIGH>,
				<0>,
				<0>,
				<0>,						/* EXTI_20 */
				<&intc GIC_SPI 12  IRQ_TYPE_LEVEL_HIGH>,
				<&intc GIC_SPI 13  IRQ_TYPE_LEVEL_HIGH>,
				<0>,
				<0>,
				<0>,
				<&intc GIC_SPI 136 IRQ_TYPE_LEVEL_HIGH>,
				<0>,
				<0>,
				<&intc GIC_SPI 181 IRQ_TYPE_LEVEL_HIGH>,
				<&intc GIC_SPI 182 IRQ_TYPE_LEVEL_HIGH>,	/* EXTI_30 */
				<&intc GIC_SPI 183 IRQ_TYPE_LEVEL_HIGH>,
				<0>,
				<0>,
				<0>,
				<&intc GIC_SPI 5   IRQ_TYPE_LEVEL_HIGH>,
				<&intc GIC_SPI 4   IRQ_TYPE_LEVEL_HIGH>,
				<&intc GIC_SPI 6   IRQ_TYPE_LEVEL_HIGH>,
				<0>,
				<&intc GIC_SPI 2   IRQ_TYPE_LEVEL_HIGH>,
				<&intc GIC_SPI 3   IRQ_TYPE_LEVEL_HIGH>,	/* EXTI_40 */
				<0>,
				<0>,
				<0>,
				<0>,
				<0>,
				<0>,
				<0>,
				<0>,
				<&intc GIC_SPI 201 IRQ_TYPE_LEVEL_HIGH>,
				<0>,						/* EXTI_50 */
				<&intc GIC_SPI 202 IRQ_TYPE_LEVEL_HIGH>,
				<&intc GIC_SPI 203 IRQ_TYPE_LEVEL_HIGH>,
				<&intc GIC_SPI 204 IRQ_TYPE_LEVEL_HIGH>;
		};

		rtc: rtc@46000000 {
			compatible = "st,stm32mp25-rtc";
			reg = <0x46000000 0x400>;
			clocks = <&rcc CK_BUS_RTC>, <&rcc RTC_CK>;
			clock-names = "pclk", "rtc_ck";
			wakeup-source;
			interrupts-extended = <&exti2 22 IRQ_TYPE_EDGE_RISING>;
		};

		tamp: tamp@46010000 {
			compatible = "st,stm32mp21-tamp";
			reg = <0x46010000 0x400>;
			clocks = <&rcc CK_BUS_RTC>;
			interrupts-extended = <&exti2 21 IRQ_TYPE_EDGE_RISING>;
			#address-cells = <1>;
			#size-cells = <1>;
			ranges;
			st,backup-zones = <24 24 24 24 12 12 8>;

			nvram: nvram@46010100 {
				compatible = "st,stm32mp25-tamp-nvram";
				#address-cells = <1>;
				#size-cells = <1>;
				reg = <0x46010100 0x200>;

				boot_mode: tamp-bkp@180 {
					reg = <0x180 0x4>;
				};
			};

			reboot_mode: reboot-mode {
				compatible = "nvmem-reboot-mode";
				nvmem-cells = <&boot_mode>;
				nvmem-cell-names = "reboot-mode";
				mode-normal = <0x00>;
				mode-fastboot = <0x01>;
				mode-recovery = <0x02>;
				mode-stm32cubeprogrammer = <0x03>;
				mode-ums_mmc0 = <0x10>;
				mode-ums_mmc1 = <0x11>;
				mode-ums_mmc2 = <0x12>;
				mode-romcode_serial = <0xff>;
			};
		};

		pinctrl_z: pinctrl@46200000 {
			#address-cells = <1>;
			#size-cells = <1>;
			compatible = "st,stm32mp215-z-pinctrl";
			ranges = <0 0x46200000 0x400>;

			gpioz: gpio@46200000 {
				gpio-controller;
				#gpio-cells = <2>;
				interrupt-controller;
				#interrupt-cells = <2>;
				#access-controller-cells = <1>;
				reg = <0 0x400>;
				clocks = <&rcc CK_BUS_GPIOZ>;
				st,bank-name = "GPIOZ";
				st,bank-ioport = <11>;
				status = "disabled";
			};
		};

		stgenc: stgen@48080000 {
			compatible = "st,stm32mp25-stgen";
			reg = <0x48080000 0x1000>;
			clocks = <&rcc CK_BUS_STGEN>, <&rcc CK_KER_STGEN>;
			clock-names = "bus", "stgen_clk";
		};

		fmc: memory-controller@48200000 {
			compatible = "st,stm32mp25-fmc2-ebi";
			reg = <0x48200000 0x400>;
			ranges = <0 0 0x70000000 0x04000000>, /* EBI CS 1 */
				 <1 0 0x74000000 0x04000000>, /* EBI CS 2 */
				 <2 0 0x78000000 0x04000000>, /* EBI CS 3 */
				 <3 0 0x7c000000 0x04000000>, /* EBI CS 4 */
				 <4 0 0x48810000 0x00001000>; /* NAND */
			#address-cells = <2>;
			#size-cells = <1>;
			clocks = <&rcc CK_KER_FMC>;
			resets = <&rcc FMC_R>;
			status = "disabled";
		};
	};

	soc1: soc@1 {
		compatible = "simple-bus";
		#address-cells = <1>;
		#size-cells = <1>;
		interrupt-parent = <&intc>;
		ranges = <0x0 0x0 0x0 0x80000000>;
	};

	mlahb: ahb@2 {
		compatible = "st,mlahb", "simple-bus";
		#address-cells = <1>;
		#size-cells = <1>;
		ranges = <0x0 0x0 0x0 0xFFFFFFFC>;
		dma-ranges = <0x00000000 0x0 0x80000000 0x08000000>,
			     <0x08000000 0x0 0x08000000 0x08000000>,
			     <0x10000000 0x0 0x80000000 0x10000000>,
			     <0x20000000 0x0 0x20000000 0xD0000000>;
		m33_rproc: m33@0 {
			compatible = "st,stm32mp2-m33";
			#reset-cells = <1>;
			reg = <0 0>;
			resets = <&rcc C2_R>,
				 <&rcc C2_HOLDBOOT_R>;
			reset-names = "mcu_rst", "hold_boot";
			status = "disabled";
		};
	};
};
